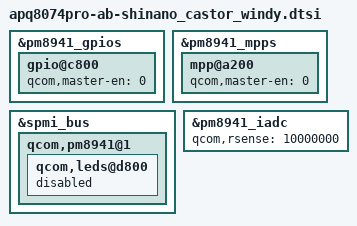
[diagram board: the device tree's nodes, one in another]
/* arch/arm/boot/dts/qcom/apq8074pro-ab-shinano_castor_windy.dtsi
 *
 * Copyright (C) 2013 Sony Mobile Communications Inc.
 *
 * Author: Kouhei Fujiya <Kouhei.X.Fujiya@sonymobile.com>
 *
 * This program is free software; you can redistribute it and/or modify
 * it under the terms of the GNU General Public License version 2 and
 * only version 2 as published by the Free Software Foundation.
 *
 * This program is distributed in the hope that it will be useful,
 * but WITHOUT ANY WARRANTY; without even the implied warranty of
 * MERCHANTABILITY or FITNESS FOR A PARTICULAR PURPOSE.  See the
 * GNU General Public License for more details.
 */

&pm8941_gpios {
	/* GPIO_9: NC */
	gpio@c800 {
		qcom,master-en = <0>;		/* Disable */
		status = "ok";
	};
};

&pm8941_mpps {
	/* MPP_3: NC (TXDAC0_VREF) */
	mpp@a200 {
		qcom,master-en = <0>;		/* Disable */
		status = "ok";
	};
};


&spmi_bus {
	qcom,pm8941@1 {
		qcom,leds@d800 {
			status = "disabled";
		};
	};
};

&pm8941_iadc {
	qcom,rsense = <10000000>;
};

